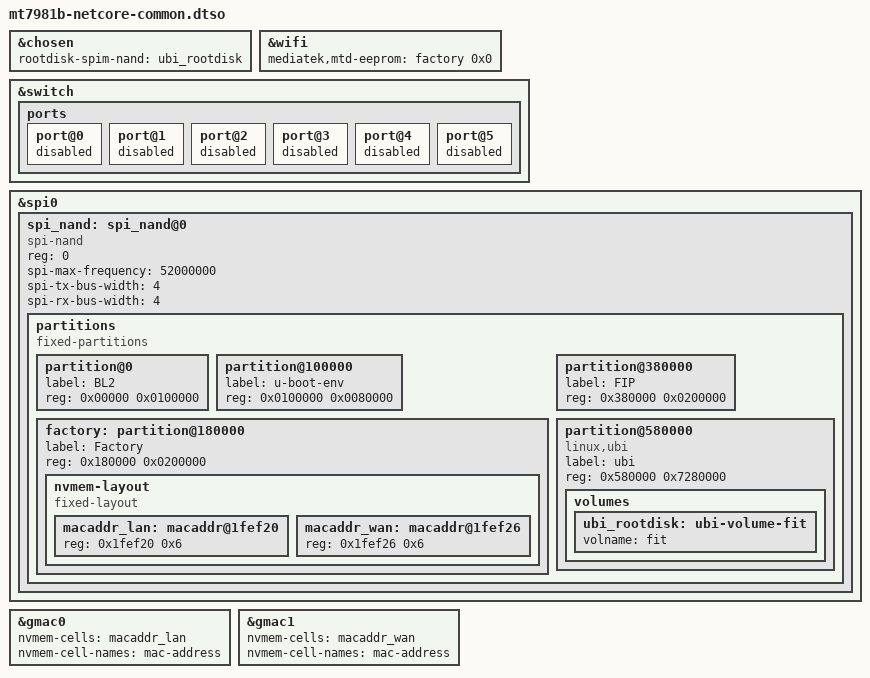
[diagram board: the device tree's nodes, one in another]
/* SPDX-License-Identifier: (GPL-2.0-only OR MIT) */
/dts-v1/;
/plugin/;

/ {

	fragment@0 {
		target = <&chosen>;
		__overlay__ {
			rootdisk-spim-nand = <&ubi_rootdisk>;
		};
	};

	fragment@1 {
		target = <&wifi>;
		__overlay__ {
			mediatek,mtd-eeprom = <&factory 0x0>;
			status = "okay";
		};
	};

	fragment@2 {
		target = <&switch>;
		__overlay__ {
			ports {
				port@0 {
					status = "disabled";
				};

				port@1 {
					status = "disabled";
				};

				port@2 {
					status = "disabled";
				};

				port@3 {
					status = "disabled";
				};

				port@4 {
					status = "disabled";
				};

				port@5 {
					status = "disabled";
				};
			};
		};
	};

	fragment@3 {
		target = <&spi0>;
		__overlay__ {
			status = "okay";
			#address-cells = <1>;
			#size-cells = <0>;

			spi_nand: spi_nand@0 {
				#address-cells = <1>;
				#size-cells = <1>;
				compatible = "spi-nand";
				reg = <0>;
				spi-max-frequency = <52000000>;
				spi-tx-bus-width = <4>;
				spi-rx-bus-width = <4>;

				partitions {
					compatible = "fixed-partitions";
					#address-cells = <1>;
					#size-cells = <1>;

					partition@0 {
						label = "BL2";
						reg = <0x00000 0x0100000>;
					};

					partition@100000 {
						label = "u-boot-env";
						reg = <0x0100000 0x0080000>;
					};

					factory: partition@180000 {
						label = "Factory";
						reg = <0x180000 0x0200000>;
					};

					partition@380000 {
						label = "FIP";
						reg = <0x380000 0x0200000>;
					};

					partition@580000 {
						label = "ubi";
						reg = <0x580000 0x7280000>;
						compatible = "linux,ubi";

						volumes {
							ubi_rootdisk: ubi-volume-fit {
								volname = "fit";
							};
						};
					};
				};
			};
		};
	};

	fragment@4 {
		target = <&factory>;
		__overlay__ {
			nvmem-layout {
				compatible = "fixed-layout";
				#address-cells = <1>;
				#size-cells = <1>;

				macaddr_lan: macaddr@1fef20 {
					reg = <0x1fef20 0x6>;
				};

				macaddr_wan: macaddr@1fef26 {
					reg = <0x1fef26 0x6>;
				};
			};
		};
	};

	fragment@5 {
		target = <&gmac0>;
		__overlay__ {
			nvmem-cells = <&macaddr_lan>;
			nvmem-cell-names = "mac-address";
		};
	};

	fragment@6 {
		target = <&gmac1>;
		__overlay__ {
			nvmem-cells = <&macaddr_wan>;
			nvmem-cell-names = "mac-address";
		};
	};

};
